# ESP32S31_RADIO register map
Vendor: Espressif; Series: ESP32-S31; File version: 3.52
Registers are 32-bit, read-write, no defined reset value unless marked. A register's access mark holds for its fields unless they carry their own. Offsets are from the block's base; [hi:lo] are bit positions; lines under a group give offsets from that group; {n}, {i} and the like mark numbered series.

## WIFI_MAC_TX_QUEUE_VECTOR — Four 0x7c-byte physical vector banks represent logical EDCA queues 3,2,1,0. The write-side Trigger-based path additionally publishes the tail of its linked MPDU-length list in the word between HE-SIG-A2 and POWER.
Base 0x20105364
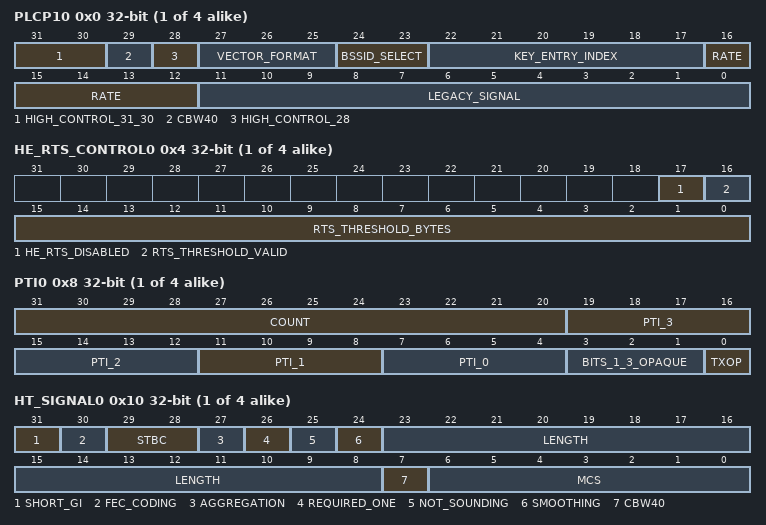
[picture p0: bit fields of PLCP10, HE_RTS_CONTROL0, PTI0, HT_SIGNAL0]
{0x0+0x7C*i} PLCP1{i} (i=0..3) — Project-assigned name. Per-queue second PLCP/vector word. Complete dbg_read_key_entry independently names bits 22:17 as KEY_ENTRY_INDEX and bits 24:23 as BSSID_SELECT. Complete libpp[hal_mac_tx.o]::mac_tx_set_plcp1 sets bit 29 for the guarded HT branch when descriptor word1 bit 15 selects 40-MHz channel width; the same selector is copied into HT-SIG1 CBW. A synchronous vendor raw HE20 MCS0 DCM capture used descriptor rate 0x1a and published 0x0401a000, proving that explicit DCM retains the ordinary 0x1a+MCS HE descriptor-code domain.
  [31:30] HIGH_CONTROL_31_30 — Project-assigned name.
  [29] CBW40 — Project-assigned name. Complete libpp[hal_mac_tx.o]::mac_tx_set_plcp1 sets this bit for the guarded non-HE HT40 branch.
  [28] HIGH_CONTROL_28 — Project-assigned name.
  [27:25] VECTOR_FORMAT — Project-assigned name. Three-bit vector family: zero for legacy, one for HT and two for HE in the reviewed paths.
  [24:23] BSSID_SELECT — Project-assigned name.
  [22:17] KEY_ENTRY_INDEX — Project-assigned name.
  [16:12] RATE — Project-assigned name. Five-bit MAC rate selector published by complete libpp[hal_mac_tx.o]::mac_tx_set_plcp1.
  [11:0] LEGACY_SIGNAL — Project-assigned name. Twelve-bit legacy PLCP SIGNAL/length value. Non-legacy formatters leave this field zero.
{0x4+0x7C*i} HE_RTS_CONTROL{i} (i=0..3) — Project-assigned name. Complete hal_he_set_tx_protection optionally replaces this word with a sixteen-bit HE byte threshold and bit 16 set, clearing the disabled flag and all upper state. With no threshold publication request it leaves this word untouched. HE Operation peer programming independently sets bit 17 in all four physical queue vectors when the encoded RTS threshold is disabled.
  [17] HE_RTS_DISABLED — Project-assigned name.
  [16] RTS_THRESHOLD_VALID — Project-assigned name. Set by the complete whole-word byte-threshold publication when argument a3 is nonzero.
  [15:0] RTS_THRESHOLD_BYTES — Project-assigned name. Low sixteen bits of hal_he_set_tx_protection argument a4. Complete libpp[pp_he.o]::ppCalTxHEAMPDULength stores the libpp[if_hwctrl.o]::ic_get_he_rts_threshold_bytes result at descriptor offset 0x34; libpp[hal_mac_tx.o]::mac_tx_set_plcp0 loads the same word into a4. This is a PHY-specific length threshold in bytes, not a frame Duration/NAV value.
{0x8+0x7C*i} PTI{i} (i=0..3) — Project-assigned name. Complete libpp[hal_mac.o]::mac_tx_set_pti publishes the original packet PTI independently into four lanes, then loads descriptor byte offset 0x22 once and passes it as argument six to hal_set_tx_pti, which publishes it as COUNT bits 31:20. This count is independent of the A-MPDU descriptor count written by libpp[hal_mac_tx.o]::mac_tx_set_mplen to HT_DESCRIPTOR_COUNTS. For vendor Authentication and Association, libnet80211[ieee80211_output.o]::ieee80211_set_tx_pti event six maps through coex_pti_tab to packet PTI one; the independent scheduler field also resolves to one through the unsigned-minimum clamp against event-one PTI five. Vendor and open HIL both used 0x00111110, including the hardware-qualified 32-MPDU open profile.
  [31:20] COUNT — Project-assigned name. Descriptor metadata byte 0x22 passed to hal_set_tx_pti; not the A-MPDU MPDU/descriptor count.
  [4n+7:4n+4] PTI_{n} (n=0..3) — Project-assigned name.
  [3:1] BITS_1_3_OPAQUE — Opaque: meaning not established.
  [0] TXOP — Project-assigned name. Complete libpp[hal_mac_tx.o]::hal_mac_tx_set_ppdu sets or clears this bit from descriptor word-zero bit 29 before libpp[hal_mac.o]::mac_tx_set_pti publishes the four coexistence lanes. The bit is independent of those lanes and must not retain the preceding queue transaction's value.
{0xC+0x7C*i} HE_CONTROL{i} (i=0..3) — Project-assigned name. Per-queue four-byte HT-Control/HE-Control image at 0x201054e4-logical_queue*0x7c. Complete hal_he_get_htc reads the whole word. Complete libpp[hal_mac_ctl.o]::hal_he_set_htc writes the supplied word before independently selecting whether this software image overrides the hardware-generated HE-Control value.
  [31:0] VALUE — Project-assigned name. Complete four-byte HE-Control image. Its A-Control subfields depend on the control ID; keep the finite protocol interpretation in the handwritten IEEE 802.11 layer rather than exposing overlapping mode-dependent SVD fields.
{0x10+0x7C*i} HT_SIGNAL{i} (i=0..3) — Project-assigned name. Complete libpp[hal_mac_tx.o]::mac_tx_set_htsig (size 0x23c) writes the packed HT-SIG1/HT-SIG2 queue image here for non-HE rates 16..35. Complete dbg_read_tx_sig independently prints the low MCS nibble and sixteen-bit length. The formatter copies descriptor word1 bit 15 to HT-SIG1 bit 7, whose standard meaning is CBW: zero selects 20 MHz and one selects 40 MHz. The exact vendor single-MPDU HT20 MCS0 callback image carried HT_SIGNAL=0x07006e00 for length 0x6e, confirming MCS zero, CBW20 and aggregate bit zero. Open HIL qualified the same single formatter at HT20 MCS0 LGI and HT40 MCS7 SGI. The independent two-MPDU HT20 MCS7/SGI capture carried 0x8f0c2e07 for aggregate length 0x0c2e, confirming aggregate bit one. The open direct-DMA A-MPDU path then received complete BlockAck for four separate HT40 MCS7/SGI two-MPDU submissions.
  [31] SHORT_GI — Project-assigned name. Standard HT-SIG2 short guard-interval bit.
  [30] FEC_CODING — Project-assigned name.
  [29:28] STBC — Project-assigned name.
  [27] AGGREGATION — Project-assigned name. Standard HT-SIG2 aggregation bit: clear for a direct MPDU and set for A-MPDU.
  [26] REQUIRED_ONE — Project-assigned name. Required one bit retained by every reviewed HT queue vector.
  [25] NOT_SOUNDING — Project-assigned name. Standard HT-SIG2 not-sounding bit; the reviewed formatter publishes one.
  [24] SMOOTHING — Project-assigned name. Standard HT-SIG2 smoothing bit; the reviewed formatter publishes one.
  [23:8] LENGTH — Project-assigned name. Sixteen-bit HT length printed by complete dbg_read_tx_sig.
  [7] CBW40 — Project-assigned name. Standard HT-SIG1 channel-width bit: zero selects 20 MHz and one selects 40 MHz.
  [6:0] MCS — Project-assigned name. Seven-bit standard HT-SIG1 MCS selector. The reviewed open 1T1R path uses MCS0 through MCS7.
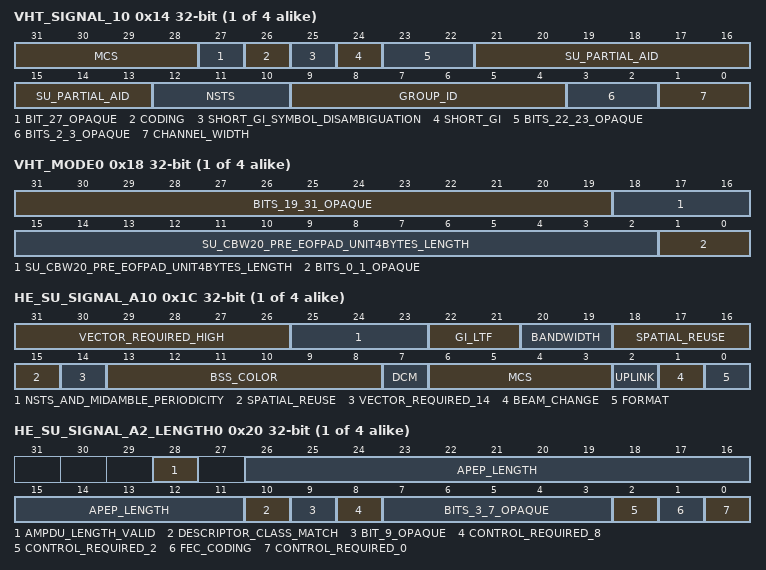
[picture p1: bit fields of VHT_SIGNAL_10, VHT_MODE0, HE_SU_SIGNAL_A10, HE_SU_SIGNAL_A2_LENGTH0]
{0x14+0x7C*i} VHT_SIGNAL_1{i} (i=0..3) — Project-assigned name. Complete dbg_read_tx_sig decodes this word only when PLCP_FORMAT is three and names VHT MCS, channel width, group ID, NSTS, SU partial AID, SGI, SGI symbol disambiguation and coding. This maps an internal hardware vector; it does not assert that the ESP32-S31 public Wi-Fi mode supports VHT transmission.
  [31:28] MCS — Project-assigned name.
  [27] BIT_27_OPAQUE — Opaque: meaning not established.
  [26] CODING — Project-assigned name.
  [25] SHORT_GI_SYMBOL_DISAMBIGUATION — Project-assigned name.
  [24] SHORT_GI — Project-assigned name.
  [23:22] BITS_22_23_OPAQUE — Opaque: meaning not established.
  [21:13] SU_PARTIAL_AID — Project-assigned name.
  [12:10] NSTS — Project-assigned name.
  [9:4] GROUP_ID — Project-assigned name.
  [3:2] BITS_2_3_OPAQUE — Opaque: meaning not established.
  [1:0] CHANNEL_WIDTH — Project-assigned name.
{0x18+0x7C*i} VHT_MODE{i} (i=0..3) — Project-assigned name. Complete dbg_read_tx_sig decodes this word only when PLCP_FORMAT is three and names bits 18:2 SU_CBW20_PRE_EOFPAD_UNIT4BYTES_LEN. Remaining bits are not assigned a meaning by the complete body.
  [31:19] BITS_19_31_OPAQUE — Opaque: meaning not established.
  [18:2] SU_CBW20_PRE_EOFPAD_UNIT4BYTES_LENGTH — Project-assigned name.
  [1:0] BITS_0_1_OPAQUE — Opaque: meaning not established.
{0x1C+0x7C*i} HE_SU_SIGNAL_A1{i} (i=0..3) — Project-assigned name. Complete libpp[hal_mac_tx.o]::mac_tx_set_hesig writes this HE SU vector word at 0x201054f4-q*0x7c. Live vendor MCS9 uplink images 0xfc205b4f and 0xfc605b4f independently qualify MCS nine, BSS color 27, HE20 and GI/LTF selectors one and three. A separate explicit MCS0 DCM vendor frame published 0xfc204087. Replaying the selector-one MCS9 image through the owned open DMA path received a complete 32-MPDU BlockAck on the first attempt and remained stable for more than 13,800 aggregates. Bits 31:26 are a TX-vector-required all-ones image and are not presented as on-air HE-SIG-A1 payload bits.
  [31:26] VECTOR_REQUIRED_HIGH — Project-assigned name. Complete formatter ORs 0xfc000000 before publication; both synchronous vendor captures retained all six bits.
  [25:23] NSTS_AND_MIDAMBLE_PERIODICITY — Project-assigned name. Complete dbg_dump_rx_ppdu shifts HE-SIG-A1 right by 23, masks three bits and prints the value as nsts_and_midamble_periodicity. The complete vendor private header uses the same name. A live 1T1R HE-SU RX vector 0x00e0591b with STBC set in HE-SIG-A2 produced encoding one: two space-time streams created from one spatial stream. This field is therefore not an unconditional NSS-minus-one value; with Doppler enabled it also carries midamble-periodicity information.
  [22:21] GI_LTF — Project-assigned name.
  [20:19] BANDWIDTH — Project-assigned name.
  [18:15] SPATIAL_REUSE — Project-assigned name.
  [14] VECTOR_REQUIRED_14 — Project-assigned name. Complete libpp[hal_mac_tx.o]::mac_tx_set_hesig ORs 0x40 into the second output byte before publication; both synchronous MCS9 vendor captures retained this otherwise non-payload vector bit.
  [13:8] BSS_COLOR — Project-assigned name.
  [7] DCM — Project-assigned name. Complete libpp[hal_mac_tx.o]::mac_tx_set_hesig copies descriptor-state word at offset 0x30 bit 15 into HE-SIG-A1 bit 7. Complete libpp[trc.o]::rcGetDCMMaxRate bounds the ordinary BCC DCM rate family to MCS0, MCS1 and MCS3 according to the peer DCM receive constellation. The vendor raw-TX configuration path independently set descriptor byte +0x31 bit 7 while retaining descriptor rate 0x1a, and the live formatter published HE-SIG-A1 0xfc204087. The owned open S-MPDU path reproduced that word and received an ordinary ACK with completion status zero. Rate-bounded open A-MPDUs with 30, 29 and 26 MPDUs then received BlockAck at MCS0 for the three qualified GI/LTF selectors. Explicit DCM and rate-control fallback therefore use distinct descriptor-code domains; BPSK DCM TX is hardware-qualified for both S-MPDU and multi-subframe A-MPDU, while QPSK and 16-QAM still require a capable peer.
  [6:3] MCS — Project-assigned name.
  [2] UPLINK — Project-assigned name.
  [1] BEAM_CHANGE — Project-assigned name.
  [0] FORMAT — Project-assigned name.
{0x20+0x7C*i} HE_SU_SIGNAL_A2_LENGTH{i} (i=0..3) — Project-assigned name. Complete libpp[hal_mac_tx.o]::mac_tx_set_hesig writes this second HE SU vector word at 0x201054f8-q*0x7c. It combines a bounded low control image with the complete HE APEP byte length shifted by eleven and a frame-class bit copied to bit 28. A-MPDU length 0x76 produced 0x1003b105; the live vendor throughput path independently reported length 0x061a in 0x1030d105. Complete libpp[pp_he.o]::ppCalSubFrameLength adds four to APEP when DMA metadata byte seven bit zero selects hardware HE-Control insertion, while leaving the low fourteen-bit MPDU length and DMA CCMP position unchanged. The vendor and open 24-byte raw S-MPDU paths both use APEP length 32, producing 0x00010105 with bit 28 clear.
  [28] AMPDU_LENGTH_VALID — Project-assigned name. Copy of frame-state bit 12; set in live HE A-MPDU images and clear in the acknowledged HE S-MPDU image.
  [26:11] APEP_LENGTH — Project-assigned name. Sixteen-bit assembled HE APEP byte count produced by libpp[pp_he.o]::ppCalTxHEAMPDULength or libpp[pp_he.o]::ppCalTxHESMPDULength and copied by libpp[hal_mac_tx.o]::mac_tx_set_hesig. For A-MPDU, DMA metadata byte seven bit zero contributes the four-byte hardware HE-Control insertion without changing the low fourteen-bit MPDU length. The qualified S-MPDU value is 32 bytes: four-byte delimiter plus 24-byte MPDU, four-byte hardware FCS slot and alignment.
  [10] DESCRIPTOR_CLASS_MATCH — Project-assigned name. Set exactly when descriptor byte 0x2f bits 6:3 equal seven.
  [9] BIT_9_OPAQUE — Opaque: meaning not established.
  [8] CONTROL_REQUIRED_8 — Project-assigned name. Bounded HE SU formatter-required low control bit.
  [7:3] BITS_3_7_OPAQUE — Opaque: meaning not established.
  [2] CONTROL_REQUIRED_2 — Project-assigned name. Bounded HE SU formatter-required low control bit.
  [1] FEC_CODING — Project-assigned name. Zero selects BCC and one selects LDPC in the bounded HE SU formatter.
  [0] CONTROL_REQUIRED_0 — Project-assigned name. Bounded HE SU formatter-required low control bit.
{0x24+0x7C*i} HE_MPDU_LENGTH_TAIL{i} (i=0..3) — Project-assigned name. Complete libpp[hal_mac_tx.o]::mac_tx_set_mplen writes the final allocated seven-bit HE MPDU-length link index at 0x201054fc-q*0x7c when it reaches the DMA descriptor whose word zero bit 30 marks the tail. Bits 31:7 are preserved. Complete libpp[hal_mac_tx.o]::mac_tx_set_tb calls that leaf for every frame before making the queue Trigger-eligible.
  [6:0] LINK_INDEX — Project-assigned name.
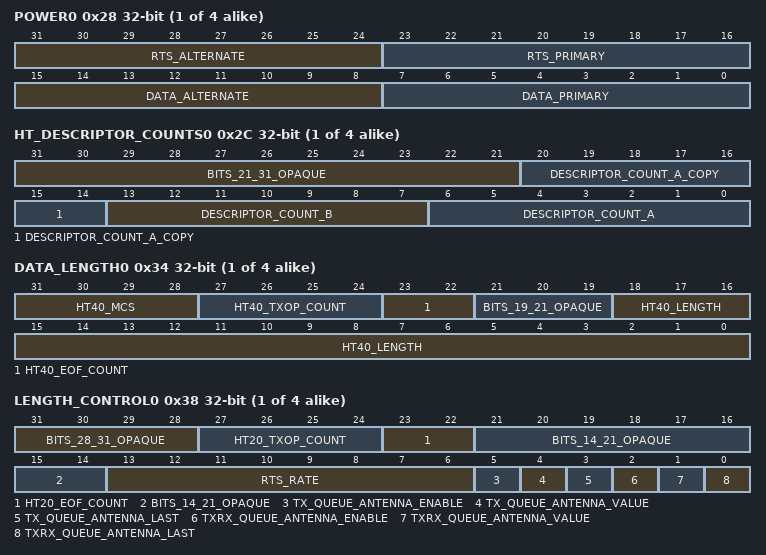
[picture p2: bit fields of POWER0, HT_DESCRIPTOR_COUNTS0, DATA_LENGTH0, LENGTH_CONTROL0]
{0x28+0x7C*i} POWER{i} (i=0..3) — Project-assigned name. Packed data/RTS PHY gain-table indices, not dBm.
  [31:24] RTS_ALTERNATE — Project-assigned name. Alternate calibrated RTS-power gain-table index.
  [23:16] RTS_PRIMARY — Project-assigned name. Primary calibrated RTS-power gain-table index.
  [15:8] DATA_ALTERNATE — Project-assigned name. Alternate calibrated data-power gain-table index.
  [7:0] DATA_PRIMARY — Project-assigned name. Primary calibrated data-power gain-table index.
{0x2C+0x7C*i} HT_DESCRIPTOR_COUNTS{i} (i=0..3) — Project-assigned name. Complete libpp[hal_mac_tx.o]::mac_tx_set_htsig constructs the base address 0x20105504-q*0x7c, then copies descriptor byte 0x2a into bits 6:0 and 20:14 and descriptor byte 0x2e into bits 13:7 through three fresh-read RMW edges. The vendor oracle read 0x00004081 for idle ordinary queues, consistent with one descriptor in all three fields. Open direct-DMA HIL first qualified two in all three lanes, then qualified the full negotiated 32-frame window with a 48,448-byte A-MPDU and complete BlockAck.
  [31:21] BITS_21_31_OPAQUE — Opaque: meaning not established.
  [20:14] DESCRIPTOR_COUNT_A_COPY — Project-assigned name. Second copy of descriptor byte 0x2a written by complete libpp[hal_mac_tx.o]::mac_tx_set_htsig.
  [13:7] DESCRIPTOR_COUNT_B — Project-assigned name. Seven-bit descriptor byte 0x2e copied by complete libpp[hal_mac_tx.o]::mac_tx_set_htsig.
  [6:0] DESCRIPTOR_COUNT_A — Project-assigned name. Seven-bit descriptor byte 0x2a copied by complete libpp[hal_mac_tx.o]::mac_tx_set_htsig.
{0x34+0x7C*i} DATA_LENGTH{i} (i=0..3) — Project-assigned name. Complete libpp[hal_mac_tx.o]::mac_tx_set_len (size 0x128) writes the packed non-HE HT data length, MCS index and entry class here. Complete dbg_read_tx_sig names the fields as the HT40 length, MCS, EOF count and TXOP count. The exact vendor single-MPDU HT20 MCS0 callback image carried 0x0000006e for length 0x6e, proving entry class zero. The independent two-MPDU MCS7 capture carried 0x70400c2e for aggregate length 0x0c2e, proving entry class one for A-MPDU. The open direct-DMA A-MPDU HIL qualified the same entry class through complete BlockAck results. Legacy formatting does not consume this queue word.
  [31:28] HT40_MCS — Project-assigned name.
  [27:24] HT40_TXOP_COUNT — Project-assigned name.
  [23:22] HT40_EOF_COUNT — Project-assigned name.
  [21:19] BITS_19_21_OPAQUE — Opaque: meaning not established.
  [18:0] HT40_LENGTH — Project-assigned name.
{0x38+0x7C*i} LENGTH_CONTROL{i} (i=0..3) — Project-assigned name. Canonical queue-vector length/rate/antenna image. Complete dbg_read_tx_sig names the low antenna-selection flags, RTS rate, HT20 EOF count and HT20 TXOP count. The upper four words of complete hal_attenna_init's eight-word traversal are these same queue-vector registers; its bit operations therefore use the canonical antenna fields below rather than a second BANK_CONTROL identity. Complete libpp[hal_mac_tx.o]::mac_tx_set_len always publishes the mac_tx_get_rts_rate result in bits 13:6, including PPDUs without explicit RTS/CTS. The exact vendor single-MPDU HT20 MCS0 callback image carried 0x000002c4, proving entry class zero; the independent two-MPDU MCS7 capture carried 0x00400244, proving entry class one. Counterintuitively, the acknowledged HE20 DCM S-MPDU also requires entry class one and carries 0x004002c4. The open direct-DMA HIL qualified both the HT aggregate and HE S-MPDU images. Complete mac_tx_get_rts_rate maps legacy OFDM 48/24/54/36 Mbit/s to basic rate 24M, 12/18M to 12M, and 6/9M to 6M.
  [31:28] BITS_28_31_OPAQUE — Opaque: meaning not established.
  [27:24] HT20_TXOP_COUNT — Project-assigned name.
  [23:22] HT20_EOF_COUNT — Project-assigned name.
  [21:14] BITS_14_21_OPAQUE — Opaque: meaning not established.
  [13:6] RTS_RATE — Project-assigned name.
  [5] TX_QUEUE_ANTENNA_ENABLE — Project-assigned name.
  [4] TX_QUEUE_ANTENNA_VALUE — Project-assigned name.
  [3] TX_QUEUE_ANTENNA_LAST — Project-assigned name.
  [2] TXRX_QUEUE_ANTENNA_ENABLE — Project-assigned name.
  [1] TXRX_QUEUE_ANTENNA_VALUE — Project-assigned name.
  [0] TXRX_QUEUE_ANTENNA_LAST — Project-assigned name.
{0x40+0x7C*i} HE_CONTROL_CONFIG{i} (i=0..3) — Project-assigned name. Per-queue control word at 0x20105518-logical_queue*0x7c. Complete libpp[hal_mac_ctl.o]::hal_he_set_htc performs a fresh-read RMW of bit 28 after publishing HE_CONTROL: nonzero enable sets the bit and zero clears it. The vendor descriptor path supplies descriptor state bit 16, which is set only for an explicit software HE-Control image such as OMC; leaving it clear permits the hardware-generated BSR path selected by the QoS frame Order bit and Trigger-eligible TID state. Vendor DMA/air HIL proves that hardware inserts the four-byte HE-Control field between QoS Control and CCMP. The DMA buffer contains no placeholder; complete libpp[pp_he.o]::ppCalSubFrameLength accounts for the insertion through metadata byte seven bit zero. Open-driver HIL independently qualifies the same contract through WPA2, decrypted ARP and ICMP traffic.
  [28] SOFTWARE_HE_CONTROL_ENABLE — Project-assigned name. Use the software HE_CONTROL word instead of the hardware-generated HE-Control value.
